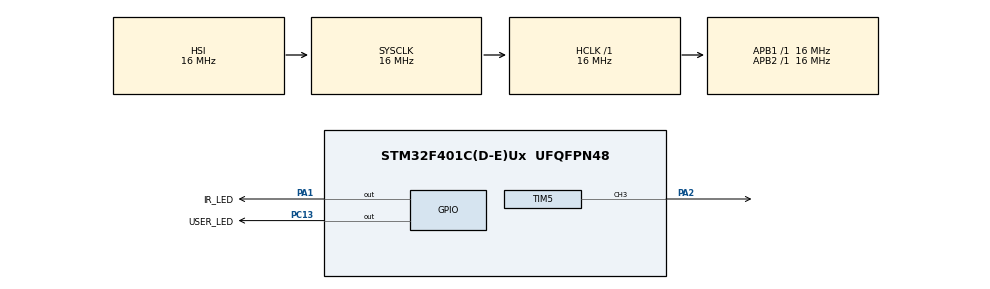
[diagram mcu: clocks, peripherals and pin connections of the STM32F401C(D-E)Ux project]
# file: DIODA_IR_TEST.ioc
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Mcu.Family=STM32F4
Mcu.Name=STM32F401C(D-E)Ux
Mcu.Package=UFQFPN48
NVIC.PriorityGroup=NVIC_PRIORITYGROUP_4
NVIC.TIM2_IRQn=true\:0\:0\:false\:false\:true\:true\:true
PA1.GPIO_Label=IR_LED
PA1.Signal=GPIO_Output
PA2.Signal=S_TIM5_CH3
PC13-ANTI_TAMP.GPIO_Label=USER_LED
PC13-ANTI_TAMP.GPIO_PuPd=GPIO_PULLUP
PC13-ANTI_TAMP.Signal=GPIO_Output
ProjectManager.HeapSize=0x200
ProjectManager.StackSize=0x400
ProjectManager.TargetToolchain=MDK-ARM V5.27
RCC.AHBFreq_Value=16000000
RCC.APB1Freq_Value=16000000
RCC.APB2Freq_Value=16000000
RCC.CortexFreq_Value=16000000
RCC.HSE_VALUE=25000000
RCC.HSI_VALUE=16000000
RCC.LSE_VALUE=32768
RCC.SYSCLKFreq_VALUE=16000000
RCC.VCOOutputFreq_Value=192000000
SH.S_TIM5_CH3.0=TIM5_CH3,PWM Generation3 CH3
TIM2.Period=1000-1
TIM2.Prescaler=16000-1
TIM5.Channel-PWM\ Generation3\ CH3=TIM_CHANNEL_3
TIM5.Period=1000-1
TIM5.Prescaler=16000-1
VP_TIM2_VS_ClockSourceINT.Mode=Internal
VP_TIM5_VS_ClockSourceINT.Mode=Internal
board=custom

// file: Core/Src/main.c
/* USER CODE BEGIN Header */
/**
  ******************************************************************************
  * @file           : main.c
  * @brief          : Main program body
  ******************************************************************************
  * @attention
  *
  * <h2><center>&copy; Copyright (c) 2021 STMicroelectronics.
  * All rights reserved.</center></h2>
  *
  * This software component is licensed by ST under BSD 3-Clause license,
  * the "License"; You may not use this file except in compliance with the
  * License. You may obtain a copy of the License at:
  *                        opensource.org/licenses/BSD-3-Clause
  *
  ******************************************************************************
  */
/* USER CODE END Header */
#include "main.h"

TIM_HandleTypeDef htim2;
TIM_HandleTypeDef htim5;

/* USER CODE BEGIN PV */
uint32_t tick = 0;
/* USER CODE END PV */

void SystemClock_Config(void);
static void MX_GPIO_Init(void);
static void MX_TIM2_Init(void);
static void MX_TIM5_Init(void);

int main(void)
{

  /* MCU Configuration--------------------------------------------------------*/

  /* Reset of all peripherals, Initializes the Flash interface and the Systick. */
  HAL_Init();

  /* Configure the system clock */
  SystemClock_Config();

  /* Initialize all configured peripherals */
  MX_GPIO_Init();
  MX_TIM2_Init();
  MX_TIM5_Init();
  /* USER CODE BEGIN 2 */
	HAL_GPIO_WritePin(USER_LED_GPIO_Port,USER_LED_Pin,GPIO_PIN_RESET);
	//HAL_TIM_Base_Start_IT(&htim2);
	HAL_TIM_PWM_Start(&htim5, TIM_CHANNEL_3);
  /* USER CODE END 2 */

  /* Infinite loop */
  while (1)
  {

    /* USER CODE BEGIN 3 */

//		for (uint16_t i = 0; i <= 1000; i ++){
//		__HAL_TIM_SetCompare(&htim5, TIM_CHANNEL_3, i);
//			HAL_Delay(2);
//		}

		__HAL_TIM_SetCompare(&htim5, TIM_CHANNEL_3, 100);
		HAL_Delay(5000);

		__HAL_TIM_SetCompare(&htim5, TIM_CHANNEL_3, 500);
		HAL_Delay(5000);

		__HAL_TIM_SetCompare(&htim5, TIM_CHANNEL_3, 1000);
		HAL_Delay(5000);

//		HAL_Delay(2000);
//
//		HAL_GPIO_WritePin(USER_LED_GPIO_Port,USER_LED_Pin,GPIO_PIN_RESET);
//		HAL_GPIO_WritePin(IR_LED_GPIO_Port,IR_LED_Pin,GPIO_PIN_SET);

//		HAL_TIM_Base_Start_IT(&htim2);

  }
  /* USER CODE END 3 */
}

void SystemClock_Config(void)
{
  RCC_OscInitTypeDef RCC_OscInitStruct = {0};
  RCC_ClkInitTypeDef RCC_ClkInitStruct = {0};

  /** Configure the main internal regulator output voltage
  */
  __HAL_RCC_PWR_CLK_ENABLE();
  __HAL_PWR_VOLTAGESCALING_CONFIG(PWR_REGULATOR_VOLTAGE_SCALE2);
  /** Initializes the RCC Oscillators according to the specified parameters
  * in the RCC_OscInitTypeDef structure.
  */
  RCC_OscInitStruct.OscillatorType = RCC_OSCILLATORTYPE_HSI;
  RCC_OscInitStruct.HSIState = RCC_HSI_ON;
  RCC_OscInitStruct.HSICalibrationValue = RCC_HSICALIBRATION_DEFAULT;
  RCC_OscInitStruct.PLL.PLLState = RCC_PLL_NONE;
  if (HAL_RCC_OscConfig(&RCC_OscInitStruct) != HAL_OK)
  {
    Error_Handler();
  }
  /** Initializes the CPU, AHB and APB buses clocks
  */
  RCC_ClkInitStruct.ClockType = RCC_CLOCKTYPE_HCLK|RCC_CLOCKTYPE_SYSCLK
                              |RCC_CLOCKTYPE_PCLK1|RCC_CLOCKTYPE_PCLK2;
  RCC_ClkInitStruct.SYSCLKSource = RCC_SYSCLKSOURCE_HSI;
  RCC_ClkInitStruct.AHBCLKDivider = RCC_SYSCLK_DIV1;
  RCC_ClkInitStruct.APB1CLKDivider = RCC_HCLK_DIV1;
  RCC_ClkInitStruct.APB2CLKDivider = RCC_HCLK_DIV1;

  if (HAL_RCC_ClockConfig(&RCC_ClkInitStruct, FLASH_LATENCY_0) != HAL_OK)
  {
    Error_Handler();
  }
}

static void MX_TIM2_Init(void)
{

  TIM_ClockConfigTypeDef sClockSourceConfig = {0};
  TIM_MasterConfigTypeDef sMasterConfig = {0};

  htim2.Instance = TIM2;
  htim2.Init.Prescaler = 16000-1;
  htim2.Init.CounterMode = TIM_COUNTERMODE_UP;
  htim2.Init.Period = 1000-1;
  htim2.Init.ClockDivision = TIM_CLOCKDIVISION_DIV1;
  htim2.Init.AutoReloadPreload = TIM_AUTORELOAD_PRELOAD_DISABLE;
  if (HAL_TIM_Base_Init(&htim2) != HAL_OK)
  {
    Error_Handler();
  }
  sClockSourceConfig.ClockSource = TIM_CLOCKSOURCE_INTERNAL;
  if (HAL_TIM_ConfigClockSource(&htim2, &sClockSourceConfig) != HAL_OK)
  {
    Error_Handler();
  }
  sMasterConfig.MasterOutputTrigger = TIM_TRGO_RESET;
  sMasterConfig.MasterSlaveMode = TIM_MASTERSLAVEMODE_DISABLE;
  if (HAL_TIMEx_MasterConfigSynchronization(&htim2, &sMasterConfig) != HAL_OK)
  {
    Error_Handler();
  }

}

static void MX_TIM5_Init(void)
{

  TIM_MasterConfigTypeDef sMasterConfig = {0};
  TIM_OC_InitTypeDef sConfigOC = {0};

  htim5.Instance = TIM5;
  htim5.Init.Prescaler = 16-1;
  htim5.Init.CounterMode = TIM_COUNTERMODE_UP;
  htim5.Init.Period = 1000-1;
  htim5.Init.ClockDivision = TIM_CLOCKDIVISION_DIV1;
  htim5.Init.AutoReloadPreload = TIM_AUTORELOAD_PRELOAD_DISABLE;
  if (HAL_TIM_PWM_Init(&htim5) != HAL_OK)
  {
    Error_Handler();
  }
  sMasterConfig.MasterOutputTrigger = TIM_TRGO_RESET;
  sMasterConfig.MasterSlaveMode = TIM_MASTERSLAVEMODE_DISABLE;
  if (HAL_TIMEx_MasterConfigSynchronization(&htim5, &sMasterConfig) != HAL_OK)
  {
    Error_Handler();
  }
  sConfigOC.OCMode = TIM_OCMODE_PWM1;
  sConfigOC.Pulse = 0;
  sConfigOC.OCPolarity = TIM_OCPOLARITY_HIGH;
  sConfigOC.OCFastMode = TIM_OCFAST_DISABLE;
  if (HAL_TIM_PWM_ConfigChannel(&htim5, &sConfigOC, TIM_CHANNEL_3) != HAL_OK)
  {
    Error_Handler();
  }
  HAL_TIM_MspPostInit(&htim5);

}

static void MX_GPIO_Init(void)
{
  GPIO_InitTypeDef GPIO_InitStruct = {0};

  /* GPIO Ports Clock Enable */
  __HAL_RCC_GPIOC_CLK_ENABLE();
  __HAL_RCC_GPIOA_CLK_ENABLE();

  /*Configure GPIO pin Output Level */
  HAL_GPIO_WritePin(USER_LED_GPIO_Port, USER_LED_Pin, GPIO_PIN_RESET);

  /*Configure GPIO pin Output Level */
  HAL_GPIO_WritePin(IR_LED_GPIO_Port, IR_LED_Pin, GPIO_PIN_RESET);

  /*Configure GPIO pin : USER_LED_Pin */
  GPIO_InitStruct.Pin = USER_LED_Pin;
  GPIO_InitStruct.Mode = GPIO_MODE_OUTPUT_PP;
  GPIO_InitStruct.Pull = GPIO_PULLUP;
  GPIO_InitStruct.Speed = GPIO_SPEED_FREQ_LOW;
  HAL_GPIO_Init(USER_LED_GPIO_Port, &GPIO_InitStruct);

  /*Configure GPIO pin : IR_LED_Pin */
  GPIO_InitStruct.Pin = IR_LED_Pin;
  GPIO_InitStruct.Mode = GPIO_MODE_OUTPUT_PP;
  GPIO_InitStruct.Pull = GPIO_NOPULL;
  GPIO_InitStruct.Speed = GPIO_SPEED_FREQ_LOW;
  HAL_GPIO_Init(IR_LED_GPIO_Port, &GPIO_InitStruct);

}

/* USER CODE BEGIN 4 */
void TIM2_IRQHandler(void)
{
  /* USER CODE BEGIN TIM2_IRQn 0 */

//	tick++;
//
//	if(tick >= 25){
//
//	HAL_GPIO_WritePin(USER_LED_GPIO_Port,USER_LED_Pin,GPIO_PIN_SET);
//	HAL_GPIO_WritePin(IR_LED_GPIO_Port,IR_LED_Pin,GPIO_PIN_RESET);
//
//	tick = 0;
//	HAL_TIM_Base_Stop_IT(&htim2);
//	}
	tick++;

	if(tick >= 3){
	HAL_GPIO_TogglePin(USER_LED_GPIO_Port,USER_LED_Pin);
	HAL_GPIO_TogglePin(IR_LED_GPIO_Port,IR_LED_Pin);
		tick = 0;
	}
  /* USER CODE END TIM2_IRQn 0 */
  HAL_TIM_IRQHandler(&htim2);
  /* USER CODE BEGIN TIM2_IRQn 1 */

  /* USER CODE END TIM2_IRQn 1 */
}
/* USER CODE END 4 */

void Error_Handler(void)
{
  __disable_irq();
  while (1)
  {
  }
}

/************************ (C) COPYRIGHT STMicroelectronics *****END OF FILE****/
